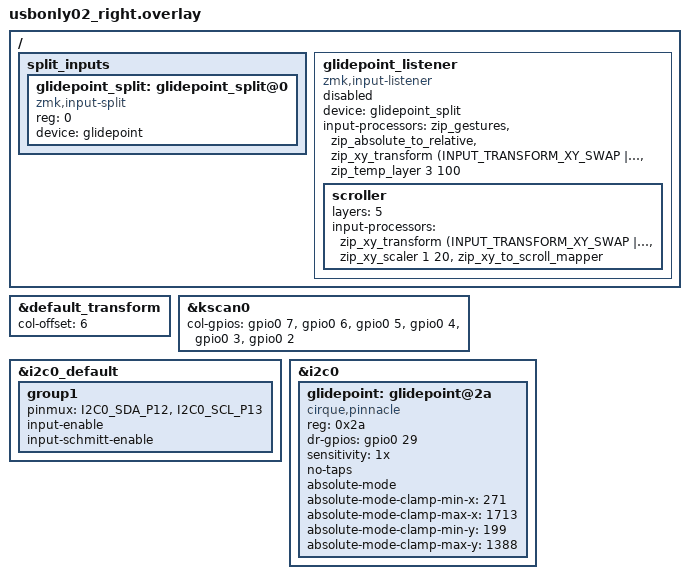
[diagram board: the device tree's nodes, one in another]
#include "usbonly02.dtsi"

#include <dt-bindings/zmk/input_transform.h>
#include <input/processors.dtsi>
#include <dt-bindings/zmk/input_transform.h>
#include <behaviors/input_processor_gestures.dtsi>
#include <behaviors/input_processor_absolute_to_relative.dtsi>

&default_transform {
    col-offset = <6>;
};

&kscan0 {
    col-gpios
        = <&gpio0 7 GPIO_ACTIVE_HIGH>
        , <&gpio0 6  GPIO_ACTIVE_HIGH>
        , <&gpio0 5  GPIO_ACTIVE_HIGH>
        , <&gpio0 4  GPIO_ACTIVE_HIGH>
        , <&gpio0 3  GPIO_ACTIVE_HIGH>
        , <&gpio0 2  GPIO_ACTIVE_HIGH>
        ;
};


&i2c0_default {
    group1 {
	    pinmux = <I2C0_SDA_P12>, <I2C0_SCL_P13>;
	    input-enable;
	    input-schmitt-enable;
	};
    status = "okay";
};

&i2c0 {
    status = "okay";

    glidepoint: glidepoint@2a {
        compatible = "cirque,pinnacle";
        reg = <0x2a>;
        status = "okay";
        dr-gpios = <&gpio0 29 (GPIO_ACTIVE_HIGH)>;

        sensitivity = "1x";
        //sleep;             
        no-taps;
        absolute-mode;

        absolute-mode-clamp-min-x=<271>;
        absolute-mode-clamp-max-x=<1713>;
        absolute-mode-clamp-min-y=<199>;
        absolute-mode-clamp-max-y=<1388>;

    };
};


&glidepoint_split {
    device = <&glidepoint>;
};



/ {
    split_inputs {
        #address-cells = <1>;
        #size-cells = <0>;

        glidepoint_split: glidepoint_split@0 {
            compatible = "zmk,input-split";
            reg = <0>;
        };
    };

    glidepoint_listener: glidepoint_listener {
        compatible = "zmk,input-listener";
        status = "disabled";
        device = <&glidepoint_split>;
    };
};

/ {
    glidepoint_listener {
        compatible = "zmk,input-listener";
        device = <&glidepoint_split>;
        
        input-processors = <
            &zip_gestures
            &zip_absolute_to_relative
            &zip_xy_transform (INPUT_TRANSFORM_XY_SWAP | INPUT_TRANSFORM_Y_INVERT)
            &zip_temp_layer 3 100
        >;
        scroller {
            layers = <5>;
            input-processors = <
                &zip_xy_transform (INPUT_TRANSFORM_XY_SWAP | INPUT_TRANSFORM_X_INVERT)
                &zip_xy_scaler 1 20
                &zip_xy_to_scroll_mapper
            >;
        };
    };
};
